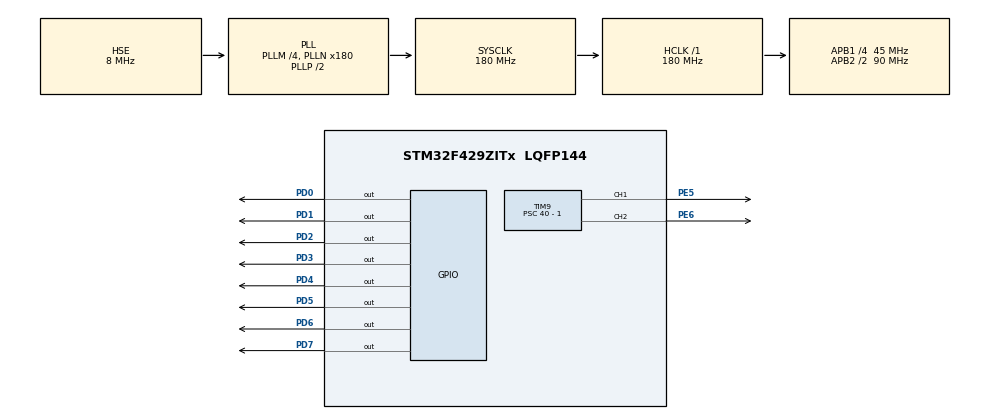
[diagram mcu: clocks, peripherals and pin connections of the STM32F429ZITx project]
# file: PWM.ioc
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Mcu.Family=STM32F4
Mcu.Name=STM32F429ZITx
Mcu.Package=LQFP144
NVIC.PriorityGroup=NVIC_PRIORITYGROUP_4
PD0.Signal=GPIO_Output
PD1.Signal=GPIO_Output
PD2.Signal=GPIO_Output
PD3.Signal=GPIO_Output
PD4.Signal=GPIO_Output
PD5.Signal=GPIO_Output
PD6.Signal=GPIO_Output
PD7.Signal=GPIO_Output
PE5.Signal=S_TIM9_CH1
PE6.Signal=S_TIM9_CH2
PH0/OSC_IN.Mode=HSE-External-Oscillator
PH0/OSC_IN.Signal=RCC_OSC_IN
PH1/OSC_OUT.Mode=HSE-External-Oscillator
PH1/OSC_OUT.Signal=RCC_OSC_OUT
ProjectManager.HeapSize=0x200
ProjectManager.StackSize=0x400
ProjectManager.TargetToolchain=MDK-ARM V5.27
RCC.48MHZClocksFreq_Value=90000000
RCC.AHBFreq_Value=180000000
RCC.APB1CLKDivider=RCC_HCLK_DIV4
RCC.APB1Freq_Value=45000000
RCC.APB1TimFreq_Value=90000000
RCC.APB2CLKDivider=RCC_HCLK_DIV2
RCC.APB2Freq_Value=90000000
RCC.APB2TimFreq_Value=180000000
RCC.CortexFreq_Value=180000000
RCC.HCLKFreq_Value=180000000
RCC.HSE_VALUE=8000000
RCC.HSI_VALUE=16000000
RCC.LSE_VALUE=32768
RCC.PLLM=4
RCC.PLLN=180
RCC.PLLSourceVirtual=RCC_PLLSOURCE_HSE
RCC.SYSCLKFreq_VALUE=180000000
RCC.SYSCLKSource=RCC_SYSCLKSOURCE_PLLCLK
RCC.VCOOutputFreq_Value=360000000
SH.S_TIM9_CH1.0=TIM9_CH1,PWM Generation1 CH1
SH.S_TIM9_CH2.0=TIM9_CH2,PWM Generation2 CH2
TIM9.Channel-PWM\ Generation1\ CH1=TIM_CHANNEL_1
TIM9.Channel-PWM\ Generation2\ CH2=TIM_CHANNEL_2
TIM9.Period=45000 - 1
TIM9.Prescaler=40 - 1
TIM9.Pulse-PWM\ Generation1\ CH1=5000 - 1
TIM9.Pulse-PWM\ Generation2\ CH2=20000 - 1
VP_TIM9_VS_ClockSourceINT.Mode=Internal
board=custom

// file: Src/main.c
/* USER CODE BEGIN Header */
/**
  ******************************************************************************
  * @file           : main.c
  * @brief          : Main program body
  ******************************************************************************
  * @attention
  *
  * <h2><center>&copy; Copyright (c) 2020 STMicroelectronics.
  * All rights reserved.</center></h2>
  *
  * This software component is licensed by ST under BSD 3-Clause license,
  * the "License"; You may not use this file except in compliance with the
  * License. You may obtain a copy of the License at:
  *                        opensource.org/licenses/BSD-3-Clause
  *
  ******************************************************************************
  */
/* USER CODE END Header */

#include "main.h"
#include "tim.h"
#include "gpio.h"

/* USER CODE BEGIN PV */
uint16_t ccr = 0;

/* USER CODE END PV */

void SystemClock_Config(void);

int main(void)
{

  /* MCU Configuration--------------------------------------------------------*/

  /* Reset of all peripherals, Initializes the Flash interface and the Systick. */
  HAL_Init();

  /* Configure the system clock */
  SystemClock_Config();

  /* Initialize all configured peripherals */
  MX_GPIO_Init();
  MX_TIM9_Init();
  /* USER CODE BEGIN 2 */
	HAL_TIM_PWM_Start(&htim9, TIM_CHANNEL_1);
	HAL_TIM_PWM_Start(&htim9, TIM_CHANNEL_2);
	HAL_GPIO_WritePin(GPIOD, GPIO_PIN_7, GPIO_PIN_SET);

  /* USER CODE END 2 */

  /* Infinite loop */
  /* USER CODE BEGIN WHILE */
  while (1)
  {
		for (ccr = 0; ccr < TIM9->ARR; ccr += 100) {
			TIM9->CCR2 = ccr;
			if (ccr > TIM9->ARR) ccr = 0;
			HAL_Delay(5);
		}
    /* USER CODE END WHILE */

  }
}

void SystemClock_Config(void)
{
  RCC_OscInitTypeDef RCC_OscInitStruct = {0};
  RCC_ClkInitTypeDef RCC_ClkInitStruct = {0};

  /** Configure the main internal regulator output voltage
  */
  __HAL_RCC_PWR_CLK_ENABLE();
  __HAL_PWR_VOLTAGESCALING_CONFIG(PWR_REGULATOR_VOLTAGE_SCALE1);
  /** Initializes the CPU, AHB and APB busses clocks
  */
  RCC_OscInitStruct.OscillatorType = RCC_OSCILLATORTYPE_HSE;
  RCC_OscInitStruct.HSEState = RCC_HSE_ON;
  RCC_OscInitStruct.PLL.PLLState = RCC_PLL_ON;
  RCC_OscInitStruct.PLL.PLLSource = RCC_PLLSOURCE_HSE;
  RCC_OscInitStruct.PLL.PLLM = 4;
  RCC_OscInitStruct.PLL.PLLN = 180;
  RCC_OscInitStruct.PLL.PLLP = RCC_PLLP_DIV2;
  RCC_OscInitStruct.PLL.PLLQ = 4;
  if (HAL_RCC_OscConfig(&RCC_OscInitStruct) != HAL_OK)
  {
    Error_Handler();
  }
  /** Activate the Over-Drive mode
  */
  if (HAL_PWREx_EnableOverDrive() != HAL_OK)
  {
    Error_Handler();
  }
  /** Initializes the CPU, AHB and APB busses clocks
  */
  RCC_ClkInitStruct.ClockType = RCC_CLOCKTYPE_HCLK|RCC_CLOCKTYPE_SYSCLK
                              |RCC_CLOCKTYPE_PCLK1|RCC_CLOCKTYPE_PCLK2;
  RCC_ClkInitStruct.SYSCLKSource = RCC_SYSCLKSOURCE_PLLCLK;
  RCC_ClkInitStruct.AHBCLKDivider = RCC_SYSCLK_DIV1;
  RCC_ClkInitStruct.APB1CLKDivider = RCC_HCLK_DIV4;
  RCC_ClkInitStruct.APB2CLKDivider = RCC_HCLK_DIV2;

  if (HAL_RCC_ClockConfig(&RCC_ClkInitStruct, FLASH_LATENCY_5) != HAL_OK)
  {
    Error_Handler();
  }
}

void Error_Handler(void)
{
}

/************************ (C) COPYRIGHT STMicroelectronics *****END OF FILE****/
